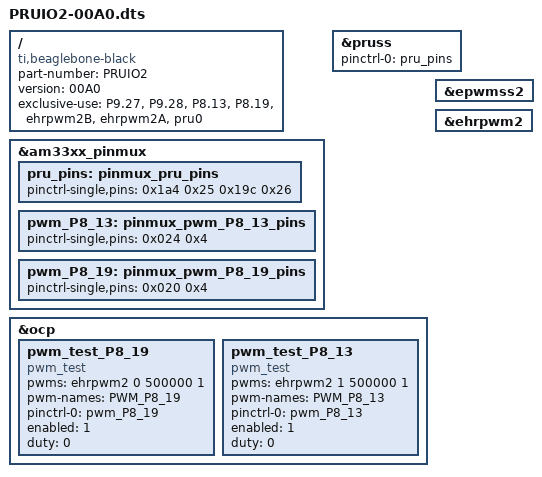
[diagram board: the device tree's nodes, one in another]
/* Compile this with "dtc -O dtb -o PRUIO-00A0.dtbo -b 0 -@ PRUIO-00A0.dts" */
/* Then copy the .dtbo file to '/lib/firmware'                              */

/dts-v1/;
/plugin/;

/{
        /* I've only tested this on the beaglebone-black */
        compatible = "ti,beaglebone-black";

        part-number = "PRUIO2";
        version = "00A0";

        exclusive-use =
                "P9.27",
                "P9.28",
                "P8.13",
                "P8.19",
                "ehrpwm2B",
                "ehrpwm2A",
                "pru0";

        fragment@0 {
                target = <&am33xx_pinmux>;
                __overlay__ {
                        pru_pins: pinmux_pru_pins {
                                pinctrl-single,pins = <
                                        0x1a4 0x25 /* set P9.27 to mode 5 - PRU_WRITE */
                                        0x19c 0x26 /* set P9.28 to mode 6 - PRU_READ  */
                                >;
                        };

                        pwm_P8_13: pinmux_pwm_P8_13_pins {
                                pinctrl-single,pins = <0x024  0x4>; /* set P8.13 to MODE 4 */
                        };

                        pwm_P8_19: pinmux_pwm_P8_19_pins {
                                pinctrl-single,pins = <0x020  0x4>; /* set P8.19 to MODE 4 */
                        };
                };
        };

        /* this fragment is included so one can experiment with PWM & GPIO at the same time */
        fragment@1 {
                target = <&pruss>;
                __overlay__ {
                        /* enable pru subsytem - equivalent to 'modprobe uio_pruss' */
                        status = "okay";
                        
                        pinctrl-names = "default";
                        /* assign pins to the subsystem */
                        pinctrl-0 = <&pru_pins>;
                };
        };

        fragment@2 {
                target = <&ocp>;
                __overlay__ {
                        pwm_test_P8_19 {
                                compatible      = "pwm_test";
                                pwms            = <&ehrpwm2 0 500000 1>; /* <device channel period ?> */
                                pwm-names       = "PWM_P8_19";

                                pinctrl-names   = "default";
                                pinctrl-0       = <&pwm_P8_19>;

                                enabled         = <1>;
                                duty            = <0>;
                                status          = "okay";
                        };

                        pwm_test_P8_13 {
                                compatible      = "pwm_test";
                                pwms            = <&ehrpwm2 1 500000 1>;
                                pwm-names       = "PWM_P8_13";

                                pinctrl-names   = "default";
                                pinctrl-0       = <&pwm_P8_13>;

                                enabled         = <1>;
                                duty            = <0>;
                                status          = "okay";
                        };
                };
        };

        fragment@3 {
                target = <&epwmss2>;
                __overlay__ {
                        status = "okay";
                };
        };

        fragment@4 {
                target = <&ehrpwm2>;
                __overlay__ {
                        status = "okay";
                };
        };
};
